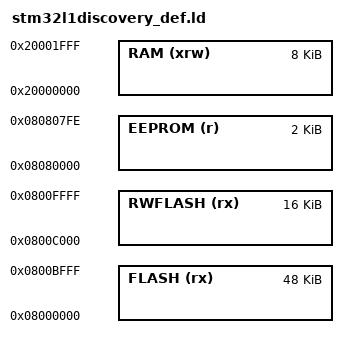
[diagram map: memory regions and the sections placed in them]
ENTRY(Reset_Handler)

MEMORY
{
  FLASH (rx) : ORIGIN = 0x08000000, LENGTH = 48K
  RWFLASH (rx) : ORIGIN = 0x08000000+48K, LENGTH = 16K
  EEPROM (r) : ORIGIN = 0x08080000, LENGTH = 0x7FF
  RAM  (xrw) : ORIGIN = 0x20000000, LENGTH = 8K
}

_estack = 0x20002000;


